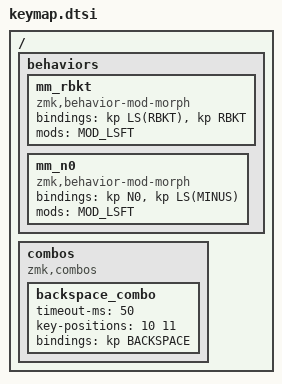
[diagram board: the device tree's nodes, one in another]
#include <behaviors.dtsi>
#include <dt-bindings/zmk/keys.h>
#include <dt-bindings/zmk/bt.h>

/ {
    behaviors {
        mm_rbkt: mm_rbkt {
            compatible = "zmk,behavior-mod-morph";
            #binding-cells = <0>;
            bindings = <&kp LS(RBKT)>, <&kp RBKT>;
            mods = <MOD_LSFT>;
        };
        mm_n0: mm_n0 {
            compatible = "zmk,behavior-mod-morph";
            #binding-cells = <0>;
            bindings = <&kp N0>, <&kp LS(MINUS)>;
            mods = <MOD_LSFT>;
        };
 };

   combos {
        compatible = "zmk,combos";
        backspace_combo {
            timeout-ms = <50>;
            key-positions = <10 11>;
            bindings = <&kp BACKSPACE>;
        };
    };
};
